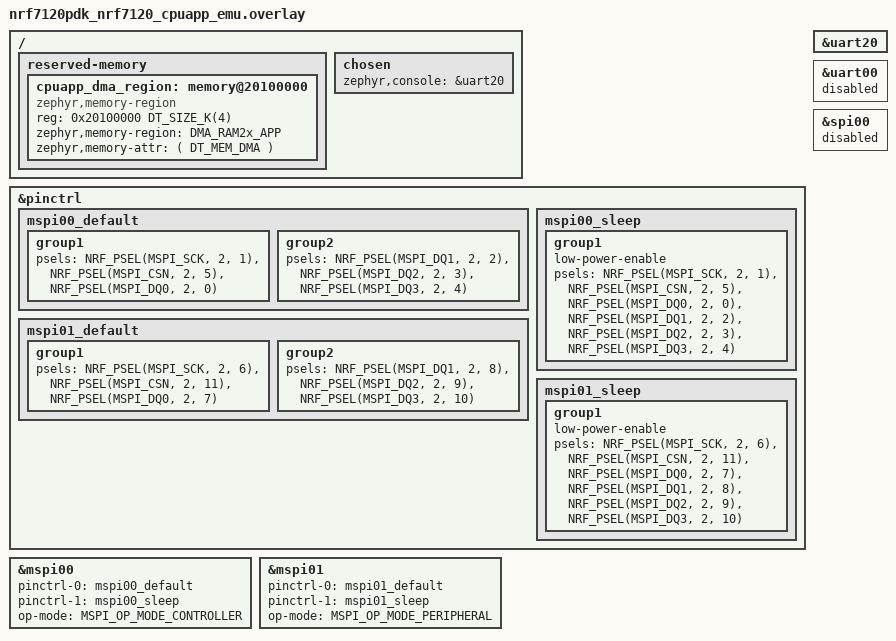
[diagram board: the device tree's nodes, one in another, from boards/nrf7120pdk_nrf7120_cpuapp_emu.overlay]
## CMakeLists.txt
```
#
# Copyright (c) 2025 Nordic Semiconductor ASA
#
# SPDX-License-Identifier: LicenseRef-Nordic-5-Clause
#

cmake_minimum_required(VERSION 3.20.0)

find_package(Zephyr REQUIRED HINTS $ENV{ZEPHYR_BASE})
project(mspi_slave)

target_sources(app PRIVATE src/main.c)
```

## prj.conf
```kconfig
#
# Copyright (c) 2025 Nordic Semiconductor ASA
#
# SPDX-License-Identifier: LicenseRef-Nordic-5-Clause
#

CONFIG_MSPI=y
CONFIG_LOG=y
CONFIG_MSPI_DMA=y

CONFIG_LOG_BUFFER_SIZE=8192
```

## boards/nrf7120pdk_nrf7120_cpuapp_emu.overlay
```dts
/*
 * QSPI01
 * Wiring required for the test:
 * Brackets is Pin on HFV FPGA board
 * - P2.6 (P0.22) SCK P7.0
 * - P2.11(P1.02) CSN P7.5
 * - P2.7 (P0.31) DQ0 P7.1
 * - P2.8 (P0.21) DQ1 P7.2
 * - P2.9 (P0.20) DQ2 P7.3
 * - P2.10(P0.23) DQ3 P7.4
 */


/*
* QSPI00
* Wiring required for the test:
* Brackets is Pin on HFV FPGA board
* - P2.1 (P0.15) SCK
* - P2.5 (P0.13) CSN
* - P2.0 (P0.7)  DQ0
* - P2.2 (P0.14) DQ1
* - P2.3 (P0.30) DQ2
* - P2.4 (P0.12) DQ3
*/

/* UART20:
	(7120) RX: P1.5 = P0.11 (FPGA BOARD)
	(7120) TX: P1.4 = P0.10 (FPGA BOARD)*/

	 // Temp CSN = P0.2 (P0.18)

#include <zephyr/dt-bindings/memory-attr/memory-attr.h>


&pinctrl {

	mspi00_default: mspi00_default {
		group1 {
			psels = <NRF_PSEL(MSPI_SCK, 2, 1)>,
					<NRF_PSEL(MSPI_CSN, 2, 5)>,
					<NRF_PSEL(MSPI_DQ0, 2, 0)>;
			// nordic,drive-mode = <NRF_DRIVE_E0E1>;
		};
		group2 {
			psels = <NRF_PSEL(MSPI_DQ1, 2, 2)>,
					<NRF_PSEL(MSPI_DQ2, 2, 3)>,
					<NRF_PSEL(MSPI_DQ3, 2, 4)>;
			// nordic,drive-mode = <NRF_DRIVE_E0E1>;
			// bias-pull-up;
		};
	};

	mspi00_sleep: mspi00_sleep {
		group1 {
			low-power-enable;
			psels = <NRF_PSEL(MSPI_SCK, 2, 1)>,
					<NRF_PSEL(MSPI_CSN, 2, 5)>,
					<NRF_PSEL(MSPI_DQ0, 2, 0)>,
					<NRF_PSEL(MSPI_DQ1, 2, 2)>,
					<NRF_PSEL(MSPI_DQ2, 2, 3)>,
					<NRF_PSEL(MSPI_DQ3, 2, 4)>;
		};
	};

	mspi01_default: mspi01_default {
		group1 {
			psels = <NRF_PSEL(MSPI_SCK, 2, 6)>,
					<NRF_PSEL(MSPI_CSN, 2, 11)>,
					<NRF_PSEL(MSPI_DQ0, 2, 7)>;
			// nordic,drive-mode = <NRF_DRIVE_E0E1>;
		};
		group2 {
			psels = <NRF_PSEL(MSPI_DQ1, 2, 8)>,
					<NRF_PSEL(MSPI_DQ2, 2, 9)>,
					<NRF_PSEL(MSPI_DQ3, 2, 10)>;
			// nordic,drive-mode = <NRF_DRIVE_E0E1>;
			// bias-pull-up;
		};
	};

	mspi01_sleep: mspi01_sleep {
		group1 {
			low-power-enable;
			psels = <NRF_PSEL(MSPI_SCK, 2, 6)>,
					<NRF_PSEL(MSPI_CSN, 2, 11)>,
					<NRF_PSEL(MSPI_DQ0, 2, 7)>,
					<NRF_PSEL(MSPI_DQ1, 2, 8)>,
					<NRF_PSEL(MSPI_DQ2, 2, 9)>,
					<NRF_PSEL(MSPI_DQ3, 2, 10)>;
		};
	};

};

/ {
	reserved-memory {
		#address-cells = <1>;
		#size-cells = <1>;
		ranges;

		cpuapp_dma_region: memory@20100000 {
			// compatible = "nordic,owned-memory", "zephyr,memory-region";
			compatible = "zephyr,memory-region";
			reg = <0x20100000 DT_SIZE_K(4)>;
			status = "okay";
			#memory-region-cells = <0>;
			// nordic,access = <NRF_OWNER_ID_APPLICATION NRF_PERM_RW>;
			zephyr,memory-region = "DMA_RAM2x_APP";
			zephyr,memory-attr = <( DT_MEM_DMA )>;
		};
	};

	chosen {
		zephyr,console = &uart20;
	};
};


&uart20{
	status = "okay";
};

&uart00{
	status = "disabled";
};

&spi00{
	status = "disabled";
};

controller:&mspi00{
	status = "okay";
	pinctrl-0 = <&mspi00_default>;
	pinctrl-1 = <&mspi00_sleep>;
	pinctrl-names = "default", "sleep";
	op-mode = "MSPI_OP_MODE_CONTROLLER";
};

peripheral:&mspi01{
	status = "okay";
	pinctrl-0 = <&mspi01_default>;
	pinctrl-1 = <&mspi01_sleep>;
	pinctrl-names = "default", "sleep";
	op-mode = "MSPI_OP_MODE_PERIPHERAL";
};
```

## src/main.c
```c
/*
 * Copyright (c) 2025 Nordic Semiconductor ASA
 *
 * SPDX-License-Identifier: LicenseRef-Nordic-5-Clause
 */

#include <zephyr/device.h>
#include <zephyr/devicetree.h>
#include <zephyr/drivers/mspi.h>
#include <zephyr/drivers/gpio.h>
#include <zephyr/logging/log.h>


LOG_MODULE_REGISTER(mspi_slave, LOG_LEVEL_DBG);


#define MSPI_PERIPHERAL_NODE 	DT_NODELABEL(peripheral)
#define MSPI_CONTROLLER_NODE 	DT_NODELABEL(controller)


#define DATA_LINES_MAX 4

#define SCK_FREQUENCY MHZ(1)

#define CMD_LEN_MAX 1
#define ADDR_LEN_MAX 3
/* Make sure it is divisible by 4 */
#define DATA_LEN_MAX 36

#define PRINT_RAW_DATA 0

static uint8_t packet_buf1[DATA_LEN_MAX + CMD_LEN_MAX + ADDR_LEN_MAX];
static uint8_t packet_buf2[DATA_LEN_MAX + CMD_LEN_MAX + ADDR_LEN_MAX];
static uint8_t packet_buf3[DATA_LEN_MAX + CMD_LEN_MAX + ADDR_LEN_MAX];


static uint8_t rx_buff1[DATA_LEN_MAX + CMD_LEN_MAX + ADDR_LEN_MAX];
static uint8_t rx_buff2[DATA_LEN_MAX + CMD_LEN_MAX + ADDR_LEN_MAX];

static const struct device *mspi_peripheral_dev 	= 	DEVICE_DT_GET(MSPI_PERIPHERAL_NODE);
static const struct device *mspi_controller_dev 	= 	DEVICE_DT_GET(MSPI_CONTROLLER_NODE);

static const struct mspi_dev_id mspi_id_tx = {
	.dev_idx = 0,
};

static const struct mspi_dev_id mspi_id_rx = {
	.dev_idx = 0,
};

void setup_buffer(void)
{

	for (int i = 0; i < DATA_LEN_MAX; ++i) {
		packet_buf1[i] = (uint8_t)i;
		packet_buf2[i] = (uint8_t)0xFF-i;
		packet_buf3[i] = (uint8_t)7;
	}
	return;
}

void print_rx_buff(uint8_t * input_buff) {
    for (size_t i = 0; i < DATA_LEN_MAX + CMD_LEN_MAX + ADDR_LEN_MAX; i++) {

        printk("returned buffer [%u] = 0x%2x\n", i, input_buff[i]);
    }
}

void async_cb(struct mspi_callback_context *mspi_cb_ctx)
{
	// volatile struct user_context *usr_ctx = mspi_cb_ctx->ctx;
	// printk("reeeeeeeeeeeeee\r\n");

	print_rx_buff(mspi_cb_ctx->mspi_evt.evt_data.packet->data_buf);
}

struct user_context {
	uint32_t status;
	uint32_t total_packets;
};

int main()
{
	setup_buffer();
	if(!device_is_ready(mspi_peripheral_dev))
	{
		LOG_ERR("MSPI device %s is not ready", mspi_peripheral_dev->name);
	}

	if(!device_is_ready(mspi_controller_dev))
	{
		LOG_ERR("MSPI device %s is not ready", mspi_controller_dev->name);
	}

	struct mspi_dev_cfg rx_dev_cfg = {
		.ce_num = 1,
		.freq = SCK_FREQUENCY,
		.io_mode = MSPI_IO_MODE_QUAD,
		.data_rate = MSPI_DATA_RATE_SINGLE,
		.cpp = MSPI_CPP_MODE_0,
		.endian = MSPI_XFER_BIG_ENDIAN,
		.ce_polarity = MSPI_CE_ACTIVE_LOW,
	};
	struct mspi_xfer_packet rx_packet1 = {
		.dir = MSPI_RX,
		.cmd = 0,
		.address = 0,
		.data_buf = rx_buff1,
		.num_bytes = DATA_LEN_MAX + CMD_LEN_MAX + ADDR_LEN_MAX,
	};
	struct mspi_xfer_packet rx_packet2 = {
		.dir = MSPI_RX,
		.cmd = 0,
		.address = 0,
		.data_buf = rx_buff2,
		.num_bytes = DATA_LEN_MAX + CMD_LEN_MAX + ADDR_LEN_MAX,
	};

	struct mspi_xfer_packet rx_packets[] = {rx_packet1, rx_packet2};

	struct mspi_xfer rx_xfer = {
		.xfer_mode   = MSPI_DMA,
		.packets     = rx_packets,
		.num_packet  = 1,
		.timeout     = 900,
		.async		 = true,
		.cmd_length = CMD_LEN_MAX,
		.addr_length = ADDR_LEN_MAX,
	};

	struct mspi_dev_cfg tx_dev_cfg = {
		.ce_num = 1,
		.freq = SCK_FREQUENCY,
		.io_mode = MSPI_IO_MODE_QUAD,
		.data_rate = MSPI_DATA_RATE_SINGLE,
		.cpp = MSPI_CPP_MODE_0,
		.endian = MSPI_XFER_BIG_ENDIAN,
		.ce_polarity = MSPI_CE_ACTIVE_LOW,
	};

	struct mspi_xfer_packet tx_packet1 = {
		.dir = MSPI_TX,
		.cmd = 0x11,
		.address = 0x222222,
		.data_buf = packet_buf1,
		.num_bytes = DATA_LEN_MAX,
	};

	struct mspi_xfer_packet tx_packet2 = {
		.dir = MSPI_TX,
		.cmd = 0x99,
		.address = 0x32,
		.data_buf = packet_buf2,
		.num_bytes = DATA_LEN_MAX,
		
	};
	struct mspi_xfer_packet tx_packet3 = {
		.dir = MSPI_TX,
		.cmd = 0x55,
		.address = 0x123456,
		.data_buf = packet_buf3,
		.num_bytes = DATA_LEN_MAX,
		
	};

	struct mspi_xfer_packet tx_packets[] = {tx_packet1, tx_packet2, tx_packet3};
	struct mspi_xfer tx_xfer = {
		.xfer_mode   = MSPI_DMA,
		.packets     = tx_packets,
		.num_packet  = 1,
		.timeout     = 900,
		.cmd_length = CMD_LEN_MAX,
		.addr_length = ADDR_LEN_MAX,
		// .async		 = true,
	};
	uint8_t cmd_lines, addr_lines, data_lines;
	cmd_lines = 4;
	addr_lines = 4;
	data_lines = 4;
	int rc;
	volatile struct user_context read_ctx;

	uint8_t cmd_addr_cycles = (tx_xfer.cmd_length * 8 / cmd_lines)
			+ (tx_xfer.addr_length * 8 / addr_lines);
	tx_xfer.tx_dummy = 0;//8 - (cmd_addr_cycles % 8);

	read_ctx.total_packets  = rx_xfer.num_packet;
	read_ctx.status         = ~0;
	struct mspi_callback_context cb_ctx;
	cb_ctx.ctx = (void *)&read_ctx;


	rc = mspi_dev_config(mspi_peripheral_dev, &mspi_id_rx,
			     MSPI_DEVICE_CONFIG_ALL, &rx_dev_cfg);
	if (rc) {
		printk("Failed to config peripheral\n");
	}
	rc = mspi_dev_config(mspi_controller_dev, &mspi_id_tx,
			     MSPI_DEVICE_CONFIG_ALL, &tx_dev_cfg);
	if (rc) {
		printk("Failed to config controller\n");
	}

	rc = mspi_register_callback(mspi_peripheral_dev, &mspi_id_rx, MSPI_BUS_XFER_COMPLETE,
					(mspi_callback_handler_t)async_cb, &cb_ctx);
	if (rc) {
		printk("Failed to register callback\n");
	}

	while(1)
	{
		printk("Setting Async rx...\r\n");
		rc = mspi_transceive(mspi_peripheral_dev, &mspi_id_rx, &rx_xfer);
		if(rc != 0)
		{
			printk("returned: %d\r\n", rc);
		}


		k_msleep(5);
		printk("- 8-bit command, 24-bit address\n");
		
		rc = mspi_transceive(mspi_controller_dev, &mspi_id_tx, &tx_xfer);
		if(rc != 0)
		{
			printk("returned: %d\r\n", rc);
		}
		k_msleep(3000);
	}
}
```
